# NAVSS0_NBSS_NB0_CFG_MMRS register map
Vendor: Texas Instruments
Peripheral module from a debugger description file (folder J7VCL).
Registers are 32-bit, read-only, reset values left out (the file's numbers can be read two ways) unless marked. A register's access mark holds for its fields unless they carry their own. Offsets are as the file gives them; lines under a group give offsets from that group; [hi:lo] are bit positions; {n}, {i} and the like mark numbered series; 'fields as' and 'values as' point back to an identical list; <NAME> marks a mode.

## NAVSS0_NBSS_NB0_CFG_MMRS
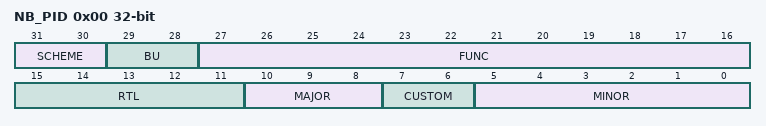
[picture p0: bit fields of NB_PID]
0x00 NB_PID — The Revision Register contains the major and minor revisions for the module.
  [31:30] SCHEME — PID register scheme
  [29:28] BU
  [27:16] FUNC — Module ID
  [15:11] RTL — RTL revision. Will vary depending on release.
  [10:8] MAJOR — Major revision
  [7:6] CUSTOM
  [5:0] MINOR — Minor revision
0x10 NB_THREADMAP rw — The Thread Map Register defines the VBUSM.C thread for each VBUSM source.
  [1:0] THREADMAP — Thread map, each bit is for each VBUSM source. Bit [0] maps orderid 0-7 to VBUSM.C thread number. Bit [1] maps orderid 8-15 to VBUSM.C thread number. 0: VBUSM.C thread 0 (non-real time traffic) 1: VBUSM.C thread 2 (real-time traffic)
